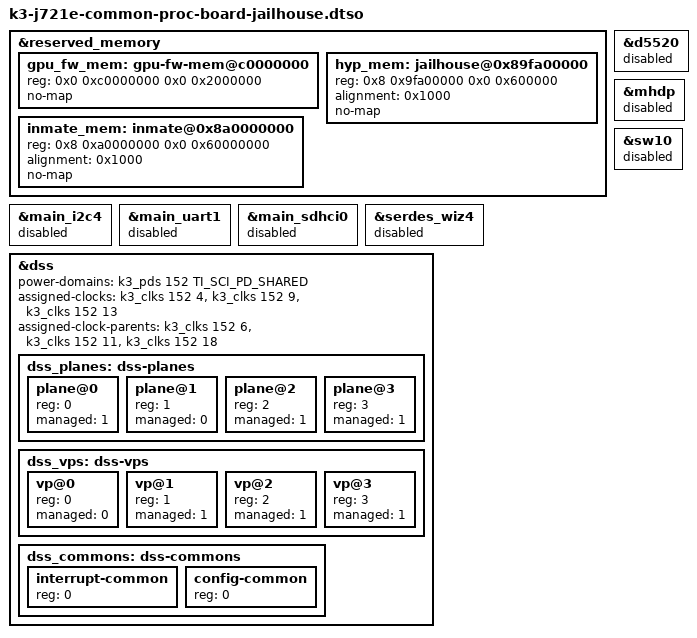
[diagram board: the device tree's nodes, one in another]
// SPDX-License-Identifier: GPL-2.0
/**
 * Infotainment Expansion Board for j721e-evm
 *
 * Copyright (C) 2019 Texas Instruments Incorporated - http://www.ti.com/
 */

/dts-v1/;
/plugin/;

#include <dt-bindings/interrupt-controller/irq.h>
#include <dt-bindings/soc/ti,sci_pm_domain.h>
#include <dt-bindings/pinctrl/k3.h>
#include <dt-bindings/gpio/gpio.h>

/dts-v1/;
/plugin/;

&reserved_memory {
	#address-cells = <2>;
	#size-cells = <2>;

	/* Reserved for GPU firmware */
	gpu_fw_mem: gpu-fw-mem@c0000000 {
		reg = <0x0 0xc0000000 0x0 0x2000000>;
		no-map;
	};

	/* Reserved for Jailhouse, IVSHMEM, baremetal apps */
	hyp_mem: jailhouse@0x89fa00000 {
		reg = <0x8 0x9fa00000 0x0 0x600000>;
		alignment = <0x1000>;
		no-map;
	};

	/* Reserved for Linux inmate */
	inmate_mem: inmate@0x8a0000000 {
		reg = <0x8 0xa0000000 0x0 0x60000000>;
		alignment = <0x1000>;
		no-map;
	};
};

&main_i2c4 {
	status = "disabled";
};

&main_uart1 {
	status = "disabled";
};

&d5520 {
	status = "disabled";
};

&main_sdhci0 {
	status = "disabled";
};

&serdes_wiz4 {
	status = "disabled";
};

&mhdp {
	status = "disabled";
};

&sw10 {
	status = "disabled";
};

&dss {
	power-domains = <&k3_pds 152 TI_SCI_PD_SHARED>; /* share IP among VMs and RTOS */

	/* No changes to parents or rates for VP 0 clocks
	 * if the VP is not owned by us
	 */

	assigned-clocks = <&k3_clks 152 4>,
		<&k3_clks 152 9>,
		<&k3_clks 152 13>;

	assigned-clock-parents = <&k3_clks 152 6>,	/* PLL19_HSDIV0 */
		<&k3_clks 152 11>,			/* PLL18_HSDIV0 */
		<&k3_clks 152 18>;			/* PLL23_HSDIV0 */

	dss_planes: dss-planes {
		#address-cells = <1>;
		#size-cells = <0>;

		/*vid1*/
		plane@0 {
			reg = <0>;
			managed = <1>;
		};

		/*vidl1*/
		plane@1 {
			reg = <1>;
			managed = <0>;
		};

		/*vid2*/
		plane@2 {
			reg = <2>;
			managed = <1>;
		};

		/*vidl2*/
		plane@3 {
			reg = <3>;
			managed = <1>;
		};
	};

	dss_vps: dss-vps {
		#address-cells = <1>;
		#size-cells = <0>;

		vp@0 {
			reg = <0>;
			managed = <0>;
		};

		vp@1 {
			reg = <1>;
			managed = <1>;
		};

		vp@2 {
			reg = <2>;
			managed = <1>;
		};

		vp@3 {
			reg = <3>;
			managed = <1>;
		};
	};

	dss_commons: dss-commons {
		#address-cells = <1>;
		#size-cells = <0>;

		interrupt-common {
			reg = <0>;
		};

		config-common {
			status = "okay";
			reg = <0>;
		};
	};
};
